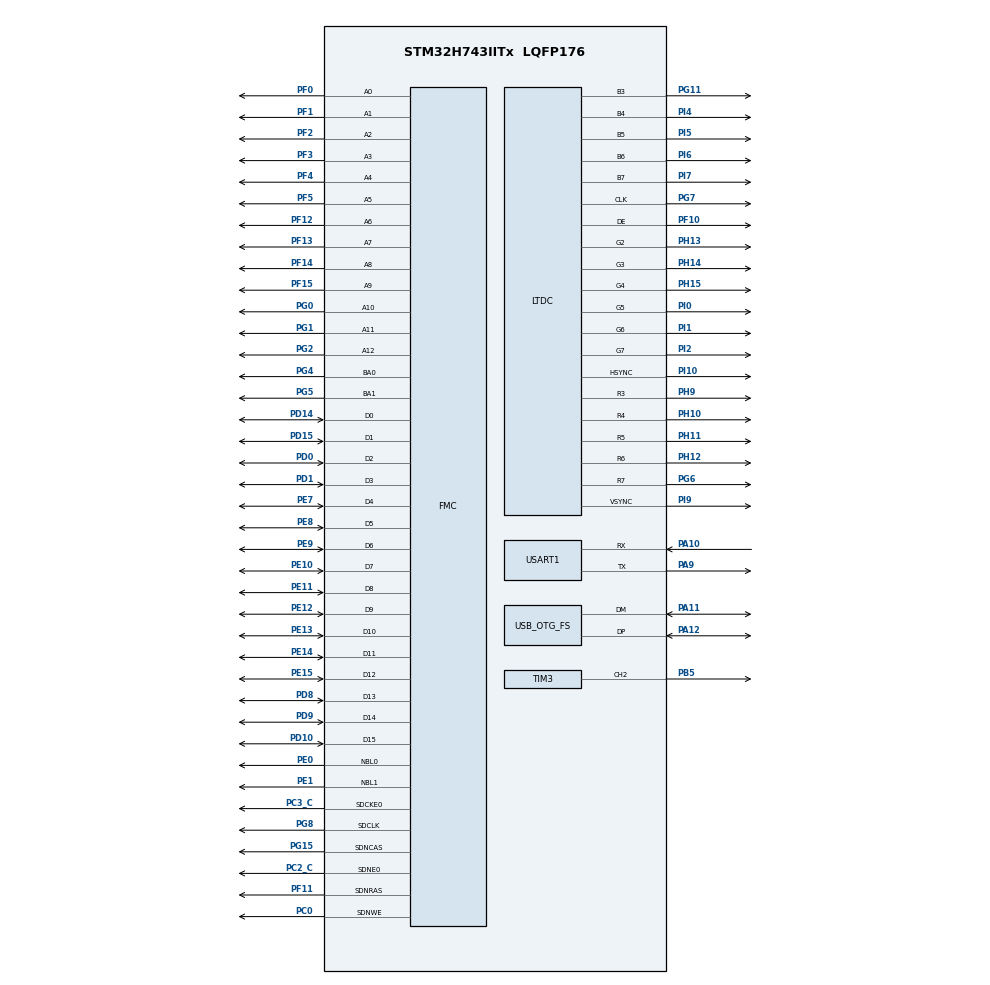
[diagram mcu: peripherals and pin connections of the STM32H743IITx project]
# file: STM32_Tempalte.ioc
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CORTEX_M7.AccessPermission-Cortex_Memory_Protection_Unit_Region0_Settings=MPU_REGION_FULL_ACCESS
CORTEX_M7.AccessPermission-Cortex_Memory_Protection_Unit_Region1_Settings=MPU_REGION_FULL_ACCESS
CORTEX_M7.BaseAddress-Cortex_Memory_Protection_Unit_Region0_Settings=0x20000000
CORTEX_M7.BaseAddress-Cortex_Memory_Protection_Unit_Region1_Settings=0xc0000000
CORTEX_M7.CPU_DCache=Enabled
CORTEX_M7.CPU_ICache=Enabled
CORTEX_M7.Enable-Cortex_Memory_Protection_Unit_Region0_Settings=MPU_REGION_ENABLE
CORTEX_M7.Enable-Cortex_Memory_Protection_Unit_Region1_Settings=MPU_REGION_ENABLE
CORTEX_M7.IsBufferable-Cortex_Memory_Protection_Unit_Region0_Settings=MPU_ACCESS_BUFFERABLE
CORTEX_M7.IsBufferable-Cortex_Memory_Protection_Unit_Region1_Settings=MPU_ACCESS_BUFFERABLE
CORTEX_M7.IsCacheable-Cortex_Memory_Protection_Unit_Region0_Settings=MPU_ACCESS_CACHEABLE
CORTEX_M7.IsCacheable-Cortex_Memory_Protection_Unit_Region1_Settings=MPU_ACCESS_CACHEABLE
CORTEX_M7.MPU_Control=MPU_PRIVILEGED_DEFAULT
CORTEX_M7.Size-Cortex_Memory_Protection_Unit_Region0_Settings=MPU_REGION_SIZE_512KB
CORTEX_M7.Size-Cortex_Memory_Protection_Unit_Region1_Settings=MPU_REGION_SIZE_32MB
DMA2D.ColorMode=DMA2D_OUTPUT_RGB565
DMA2D.Mode=DMA2D_M2M
DMA2D.OutputOffset=0
FMC.CASLatency2=FMC_SDRAM_CAS_LATENCY_2
FMC.ColumnBitsNumber2=FMC_SDRAM_COLUMN_BITS_NUM_9
FMC.ExitSelfRefreshDelay2=8
FMC.LoadToActiveDelay2=2
FMC.RCDDelay2=2
FMC.RPDelay2=2
FMC.ReadBurst2=FMC_SDRAM_RBURST_ENABLE
FMC.RowCycleDelay2=6
FMC.SDClockPeriod2=FMC_SDRAM_CLOCK_PERIOD_2
FMC.SelfRefreshTime2=6
FMC.WriteRecoveryTime2=5
LTDC.ActiveH=272
LTDC.ActiveW=480
LTDC.Alpha_L0=255
LTDC.Alpha_L1=0
LTDC.Blue=0
LTDC.FBStartAdress_L0=0xc0000000
LTDC.FBStartAdress_L1=0xc003fc00
LTDC.Green=0
LTDC.HBP=40
LTDC.HFP=5
LTDC.HSync=1
LTDC.ImageHeight_L0=272
LTDC.ImageHeight_L1=272
LTDC.ImageWidth_L0=480
LTDC.ImageWidth_L1=480
LTDC.PixelFormat_L0=LTDC_PIXEL_FORMAT_RGB565
LTDC.PixelFormat_L1=LTDC_PIXEL_FORMAT_RGB565
LTDC.Red=0
LTDC.VBP=8
LTDC.VFP=8
LTDC.VSync=1
LTDC.WindowX1_L0=480
LTDC.WindowX1_L1=480
LTDC.WindowY1_L0=272
LTDC.WindowY1_L1=272
Mcu.Family=STM32H7
Mcu.Name=STM32H743IITx
Mcu.Package=LQFP176
NVIC.OTG_FS_IRQn=true\:0\:0\:false\:false\:true\:false\:true
NVIC.PriorityGroup=NVIC_PRIORITYGROUP_4
PA10.Mode=Asynchronous
PA10.Signal=USART1_RX
PA11.Mode=Device_Only
PA11.Signal=USB_OTG_FS_DM
PA12.Mode=Device_Only
PA12.Signal=USB_OTG_FS_DP
PA13\ (JTMS/SWDIO).Mode=Serial_Wire
PA13\ (JTMS/SWDIO).Signal=DEBUG_JTMS-SWDIO
PA14\ (JTCK/SWCLK).Mode=Serial_Wire
PA14\ (JTCK/SWCLK).Signal=DEBUG_JTCK-SWCLK
PA9.Mode=Asynchronous
PA9.Signal=USART1_TX
PB5.Signal=S_TIM3_CH2
PC0.Signal=FMC_SDNWE
PC2_C.Mode=SdramChipSelect1_2
PC2_C.Signal=FMC_SDNE0
PC3_C.Mode=SdramChipSelect1_2
PC3_C.Signal=FMC_SDCKE0
PD0.Signal=FMC_D2_DA2
PD1.Signal=FMC_D3_DA3
PD10.Signal=FMC_D15_DA15
PD14.Signal=FMC_D0_DA0
PD15.Signal=FMC_D1_DA1
PD8.Signal=FMC_D13_DA13
PD9.Signal=FMC_D14_DA14
PE0.Signal=FMC_NBL0
PE1.Signal=FMC_NBL1
PE10.Signal=FMC_D7_DA7
PE11.Signal=FMC_D8_DA8
PE12.Signal=FMC_D9_DA9
PE13.Signal=FMC_D10_DA10
PE14.Signal=FMC_D11_DA11
PE15.Signal=FMC_D12_DA12
PE7.Signal=FMC_D4_DA4
PE8.Signal=FMC_D5_DA5
PE9.Signal=FMC_D6_DA6
PF0.Signal=FMC_A0
PF1.Signal=FMC_A1
PF10.Mode=RGB565
PF10.Signal=LTDC_DE
PF11.Signal=FMC_SDNRAS
PF12.Signal=FMC_A6
PF13.Signal=FMC_A7
PF14.Signal=FMC_A8
PF15.Signal=FMC_A9
PF2.Signal=FMC_A2
PF3.Signal=FMC_A3
PF4.Signal=FMC_A4
PF5.Signal=FMC_A5
PG0.Signal=FMC_A10
PG1.Signal=FMC_A11
PG11.Mode=RGB565
PG11.Signal=LTDC_B3
PG15.Signal=FMC_SDNCAS
PG2.Signal=FMC_A12
PG4.Signal=FMC_A14_BA0
PG5.Signal=FMC_A15_BA1
PG6.Mode=RGB565
PG6.Signal=LTDC_R7
PG7.Mode=RGB565
PG7.Signal=LTDC_CLK
PG8.Signal=FMC_SDCLK
PH0-OSC_IN\ (PH0).Mode=HSE-External-Oscillator
PH0-OSC_IN\ (PH0).Signal=RCC_OSC_IN
PH1-OSC_OUT\ (PH1).Mode=HSE-External-Oscillator
PH1-OSC_OUT\ (PH1).Signal=RCC_OSC_OUT
PH10.Mode=RGB565
PH10.Signal=LTDC_R4
PH11.Mode=RGB565
PH11.Signal=LTDC_R5
PH12.Mode=RGB565
PH12.Signal=LTDC_R6
PH13.Mode=RGB565
PH13.Signal=LTDC_G2
PH14.Mode=RGB565
PH14.Signal=LTDC_G3
PH15.Mode=RGB565
PH15.Signal=LTDC_G4
PH9.Mode=RGB565
PH9.Signal=LTDC_R3
PI0.Mode=RGB565
PI0.Signal=LTDC_G5
PI1.Mode=RGB565
PI1.Signal=LTDC_G6
PI10.Mode=RGB565
PI10.Signal=LTDC_HSYNC
PI2.Mode=RGB565
PI2.Signal=LTDC_G7
PI4.Mode=RGB565
PI4.Signal=LTDC_B4
PI5.Mode=RGB565
PI5.Signal=LTDC_B5
PI6.Mode=RGB565
PI6.Signal=LTDC_B6
PI7.Mode=RGB565
PI7.Signal=LTDC_B7
PI9.Mode=RGB565
PI9.Signal=LTDC_VSYNC
ProjectManager.HeapSize=0x1000
ProjectManager.StackSize=0x1000
ProjectManager.TargetToolchain=MDK-ARM V5.27
RCC.ADCFreq_Value=129000000
RCC.APB1Freq_Value=120000000
RCC.APB2Freq_Value=120000000
RCC.APB3Freq_Value=120000000
RCC.APB4Freq_Value=120000000
RCC.CortexFreq_Value=480000000
RCC.D1PPRE=RCC_APB3_DIV2
RCC.D2PPRE1=RCC_APB1_DIV2
RCC.D2PPRE2=RCC_APB2_DIV2
RCC.D3PPRE=RCC_APB4_DIV2
RCC.DIVM1=4
RCC.DIVM3=1
RCC.DIVN1=60
RCC.DIVN3=4
RCC.DIVR3=29
RCC.FMCCLockSelection=RCC_FMCCLKSOURCE_CLKP
RCC.HCLKFreq_Value=240000000
RCC.HPRE=RCC_HCLK_DIV2
RCC.PLL2FRACN=0
RCC.PLL3FRACN=640
RCC.PLLFRACN=0
RCC.SYSCLKFreq_VALUE=480000000
RCC.SYSCLKSource=RCC_SYSCLKSOURCE_PLLCLK
RCC.USBCLockSelection=RCC_USBCLKSOURCE_HSI48
RCC.USBFreq_Value=48000000
SH.FMC_A0.0=FMC_A0,13b-sda2
SH.FMC_A1.0=FMC_A1,13b-sda2
SH.FMC_A10.0=FMC_A10,13b-sda2
SH.FMC_A11.0=FMC_A11,13b-sda2
SH.FMC_A12.0=FMC_A12,13b-sda2
SH.FMC_A14_BA0.0=FMC_BA0,FourSdramBanks2
SH.FMC_A15_BA1.0=FMC_BA1,FourSdramBanks2
SH.FMC_A2.0=FMC_A2,13b-sda2
SH.FMC_A3.0=FMC_A3,13b-sda2
SH.FMC_A4.0=FMC_A4,13b-sda2
SH.FMC_A5.0=FMC_A5,13b-sda2
SH.FMC_A6.0=FMC_A6,13b-sda2
SH.FMC_A7.0=FMC_A7,13b-sda2
SH.FMC_A8.0=FMC_A8,13b-sda2
SH.FMC_A9.0=FMC_A9,13b-sda2
SH.FMC_D0_DA0.0=FMC_D0,sd-16b-d2
SH.FMC_D10_DA10.0=FMC_D10,sd-16b-d2
SH.FMC_D11_DA11.0=FMC_D11,sd-16b-d2
SH.FMC_D12_DA12.0=FMC_D12,sd-16b-d2
SH.FMC_D13_DA13.0=FMC_D13,sd-16b-d2
SH.FMC_D14_DA14.0=FMC_D14,sd-16b-d2
SH.FMC_D15_DA15.0=FMC_D15,sd-16b-d2
SH.FMC_D1_DA1.0=FMC_D1,sd-16b-d2
SH.FMC_D2_DA2.0=FMC_D2,sd-16b-d2
SH.FMC_D3_DA3.0=FMC_D3,sd-16b-d2
SH.FMC_D4_DA4.0=FMC_D4,sd-16b-d2
SH.FMC_D5_DA5.0=FMC_D5,sd-16b-d2
SH.FMC_D6_DA6.0=FMC_D6,sd-16b-d2
SH.FMC_D7_DA7.0=FMC_D7,sd-16b-d2
SH.FMC_D8_DA8.0=FMC_D8,sd-16b-d2
SH.FMC_D9_DA9.0=FMC_D9,sd-16b-d2
SH.FMC_NBL0.0=FMC_NBL0,Sd2ByteEnable2
SH.FMC_NBL1.0=FMC_NBL1,Sd2ByteEnable2
SH.FMC_SDCLK.0=FMC_SDCLK,13b-sda2
SH.FMC_SDNCAS.0=FMC_SDNCAS,13b-sda2
SH.FMC_SDNRAS.0=FMC_SDNRAS,13b-sda2
SH.FMC_SDNWE.0=FMC_SDNWE,13b-sda2
SH.S_TIM3_CH2.0=TIM3_CH2,PWM Generation2 CH2
TIM3.Channel-PWM\ Generation2\ CH2=TIM_CHANNEL_2
TIM3.Period=1000
TIM3.Prescaler=240
TIM3.Pulse-PWM\ Generation2\ CH2=500
USART1.VirtualMode-Asynchronous=VM_ASYNC
USB_DEVICE.CLASS_NAME_FS=HID
USB_DEVICE.VirtualMode-HID_FS=Hid
USB_DEVICE.VirtualModeFS=Hid_FS
USB_OTG_FS.VirtualMode=Device_Only
USB_OTG_FS.dma_enable=DISABLE
USB_OTG_FS.lpm_enable=DISABLE
VP_DMA2D_VS_DMA2D.Mode=DMA2D_Activate
VP_USB_DEVICE_VS_USB_DEVICE_HID_FS.Mode=HID_FS
board=custom

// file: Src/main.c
/* USER CODE BEGIN Header */
/**
  ******************************************************************************
  * @file           : main.c
  * @brief          : Main program body
  ******************************************************************************
  * @attention
  *
  * <h2><center>&copy; Copyright (c) 2021 STMicroelectronics.
  * All rights reserved.</center></h2>
  *
  * This software component is licensed by ST under BSD 3-Clause license,
  * the "License"; You may not use this file except in compliance with the
  * License. You may obtain a copy of the License at:
  *                        opensource.org/licenses/BSD-3-Clause
  *
  ******************************************************************************
  */
/* USER CODE END Header */

#include "main.h"
#include "dma2d.h"
#include "ltdc.h"
#include "tim.h"
#include "usart.h"
#include "usb_device.h"
#include "gpio.h"
#include "fmc.h"

/* USER CODE BEGIN Includes */
#include "sdram.h"
#include "stdio.h"
#include "lcd_lib.h"
/* USER CODE END Includes */

void SystemClock_Config(void);
static void MPU_Config(void);

int main(void)
{
  /* USER CODE BEGIN 1 */
  uint16_t i = 0;
  /* USER CODE END 1 */

  /* MPU Configuration--------------------------------------------------------*/
  MPU_Config();

  /* Enable I-Cache---------------------------------------------------------*/
  SCB_EnableICache();

  /* Enable D-Cache---------------------------------------------------------*/
  SCB_EnableDCache();

  /* MCU Configuration--------------------------------------------------------*/

  /* Reset of all peripherals, Initializes the Flash interface and the Systick. */
  HAL_Init();

  /* Configure the system clock */
  SystemClock_Config();

  /* Initialize all configured peripherals */
  MX_GPIO_Init();
  MX_LTDC_Init();
  MX_TIM3_Init();
  MX_FMC_Init();
  MX_USART1_UART_Init();
  MX_DMA2D_Init();
  MX_USB_DEVICE_Init();
  /* USER CODE BEGIN 2 */
  SDRAM_Initialization_Sequence(&hsdram2);
  HAL_TIM_Base_Start(&htim3);
  HAL_TIM_PWM_Start(&htim3, TIM_CHANNEL_2);
  /* USER CODE END 2 */

  /* Infinite loop */
  /* USER CODE BEGIN WHILE */
  //LCD_Clear(LCD_RGB(31, 63, 31));
  //LCD_ShowString(50, 50, 200, 200, 16, "hello", LCD_RGB(255, 0, 0));
  //LCD_ColorTest(10);
  LCD_Clear(LCD_RGB(100, 50, 150));
  //LCD_DrawLine(0, 0, 0, LCD_WIDTH, LCD_RGB(255, 255, 255));
  //LCD_DrawLine(10, 0, 10, LCD_WIDTH, LCD_RGB(255, 255, 255));
  while (1)
  {
    i++;
    LCD_Debug("%d", i);
    /* USER CODE END WHILE */

  }
}

void SystemClock_Config(void)
{
  RCC_OscInitTypeDef RCC_OscInitStruct = {0};
  RCC_ClkInitTypeDef RCC_ClkInitStruct = {0};
  RCC_PeriphCLKInitTypeDef PeriphClkInitStruct = {0};

  /** Supply configuration update enable
  */
  HAL_PWREx_ConfigSupply(PWR_LDO_SUPPLY);
  /** Configure the main internal regulator output voltage
  */
  __HAL_PWR_VOLTAGESCALING_CONFIG(PWR_REGULATOR_VOLTAGE_SCALE0);

  while(!__HAL_PWR_GET_FLAG(PWR_FLAG_VOSRDY)) {}
  /** Macro to configure the PLL clock source
  */
  __HAL_RCC_PLL_PLLSOURCE_CONFIG(RCC_PLLSOURCE_HSI);
  /** Initializes the CPU, AHB and APB busses clocks
  */
  RCC_OscInitStruct.OscillatorType = RCC_OSCILLATORTYPE_HSI48|RCC_OSCILLATORTYPE_HSI;
  RCC_OscInitStruct.HSIState = RCC_HSI_DIV1;
  RCC_OscInitStruct.HSICalibrationValue = RCC_HSICALIBRATION_DEFAULT;
  RCC_OscInitStruct.HSI48State = RCC_HSI48_ON;
  RCC_OscInitStruct.PLL.PLLState = RCC_PLL_ON;
  RCC_OscInitStruct.PLL.PLLSource = RCC_PLLSOURCE_HSI;
  RCC_OscInitStruct.PLL.PLLM = 4;
  RCC_OscInitStruct.PLL.PLLN = 60;
  RCC_OscInitStruct.PLL.PLLP = 2;
  RCC_OscInitStruct.PLL.PLLQ = 2;
  RCC_OscInitStruct.PLL.PLLR = 2;
  RCC_OscInitStruct.PLL.PLLRGE = RCC_PLL1VCIRANGE_3;
  RCC_OscInitStruct.PLL.PLLVCOSEL = RCC_PLL1VCOWIDE;
  RCC_OscInitStruct.PLL.PLLFRACN = 0;
  if (HAL_RCC_OscConfig(&RCC_OscInitStruct) != HAL_OK)
  {
    Error_Handler();
  }
  /** Initializes the CPU, AHB and APB busses clocks
  */
  RCC_ClkInitStruct.ClockType = RCC_CLOCKTYPE_HCLK|RCC_CLOCKTYPE_SYSCLK
                              |RCC_CLOCKTYPE_PCLK1|RCC_CLOCKTYPE_PCLK2
                              |RCC_CLOCKTYPE_D3PCLK1|RCC_CLOCKTYPE_D1PCLK1;
  RCC_ClkInitStruct.SYSCLKSource = RCC_SYSCLKSOURCE_PLLCLK;
  RCC_ClkInitStruct.SYSCLKDivider = RCC_SYSCLK_DIV1;
  RCC_ClkInitStruct.AHBCLKDivider = RCC_HCLK_DIV2;
  RCC_ClkInitStruct.APB3CLKDivider = RCC_APB3_DIV2;
  RCC_ClkInitStruct.APB1CLKDivider = RCC_APB1_DIV2;
  RCC_ClkInitStruct.APB2CLKDivider = RCC_APB2_DIV2;
  RCC_ClkInitStruct.APB4CLKDivider = RCC_APB4_DIV2;

  if (HAL_RCC_ClockConfig(&RCC_ClkInitStruct, FLASH_LATENCY_4) != HAL_OK)
  {
    Error_Handler();
  }
  PeriphClkInitStruct.PeriphClockSelection = RCC_PERIPHCLK_LTDC|RCC_PERIPHCLK_USART1
                              |RCC_PERIPHCLK_USB|RCC_PERIPHCLK_FMC
                              |RCC_PERIPHCLK_CKPER;
  PeriphClkInitStruct.PLL3.PLL3M = 1;
  PeriphClkInitStruct.PLL3.PLL3N = 4;
  PeriphClkInitStruct.PLL3.PLL3P = 2;
  PeriphClkInitStruct.PLL3.PLL3Q = 2;
  PeriphClkInitStruct.PLL3.PLL3R = 29;
  PeriphClkInitStruct.PLL3.PLL3RGE = RCC_PLL3VCIRANGE_3;
  PeriphClkInitStruct.PLL3.PLL3VCOSEL = RCC_PLL3VCOWIDE;
  PeriphClkInitStruct.PLL3.PLL3FRACN = 640;
  PeriphClkInitStruct.FmcClockSelection = RCC_FMCCLKSOURCE_CLKP;
  PeriphClkInitStruct.CkperClockSelection = RCC_CLKPSOURCE_HSI;
  PeriphClkInitStruct.Usart16ClockSelection = RCC_USART16CLKSOURCE_D2PCLK2;
  PeriphClkInitStruct.UsbClockSelection = RCC_USBCLKSOURCE_HSI48;
  if (HAL_RCCEx_PeriphCLKConfig(&PeriphClkInitStruct) != HAL_OK)
  {
    Error_Handler();
  }
  /** Enable USB Voltage detector
  */
  HAL_PWREx_EnableUSBVoltageDetector();
}

/* MPU Configuration */

void MPU_Config(void)
{
  MPU_Region_InitTypeDef MPU_InitStruct = {0};

  /* Disables the MPU */
  HAL_MPU_Disable();
  /** Initializes and configures the Region and the memory to be protected
  */
  MPU_InitStruct.Enable = MPU_REGION_ENABLE;
  MPU_InitStruct.Number = MPU_REGION_NUMBER0;
  MPU_InitStruct.BaseAddress = 0x20000000;
  MPU_InitStruct.Size = MPU_REGION_SIZE_512KB;
  MPU_InitStruct.SubRegionDisable = 0x0;
  MPU_InitStruct.TypeExtField = MPU_TEX_LEVEL0;
  MPU_InitStruct.AccessPermission = MPU_REGION_FULL_ACCESS;
  MPU_InitStruct.DisableExec = MPU_INSTRUCTION_ACCESS_ENABLE;
  MPU_InitStruct.IsShareable = MPU_ACCESS_NOT_SHAREABLE;
  MPU_InitStruct.IsCacheable = MPU_ACCESS_CACHEABLE;
  MPU_InitStruct.IsBufferable = MPU_ACCESS_BUFFERABLE;

  HAL_MPU_ConfigRegion(&MPU_InitStruct);
  /** Initializes and configures the Region and the memory to be protected
  */
  MPU_InitStruct.Enable = MPU_REGION_ENABLE;
  MPU_InitStruct.Number = MPU_REGION_NUMBER1;
  MPU_InitStruct.BaseAddress = 0xc0000000;
  MPU_InitStruct.Size = MPU_REGION_SIZE_32MB;
  MPU_InitStruct.SubRegionDisable = 0x0;
  MPU_InitStruct.TypeExtField = MPU_TEX_LEVEL0;
  MPU_InitStruct.AccessPermission = MPU_REGION_FULL_ACCESS;
  MPU_InitStruct.DisableExec = MPU_INSTRUCTION_ACCESS_ENABLE;
  MPU_InitStruct.IsShareable = MPU_ACCESS_NOT_SHAREABLE;
  MPU_InitStruct.IsCacheable = MPU_ACCESS_CACHEABLE;
  MPU_InitStruct.IsBufferable = MPU_ACCESS_BUFFERABLE;

  HAL_MPU_ConfigRegion(&MPU_InitStruct);
  /* Enables the MPU */
  HAL_MPU_Enable(MPU_PRIVILEGED_DEFAULT);

}

void Error_Handler(void)
{
}

/************************ (C) COPYRIGHT STMicroelectronics *****END OF FILE****/
